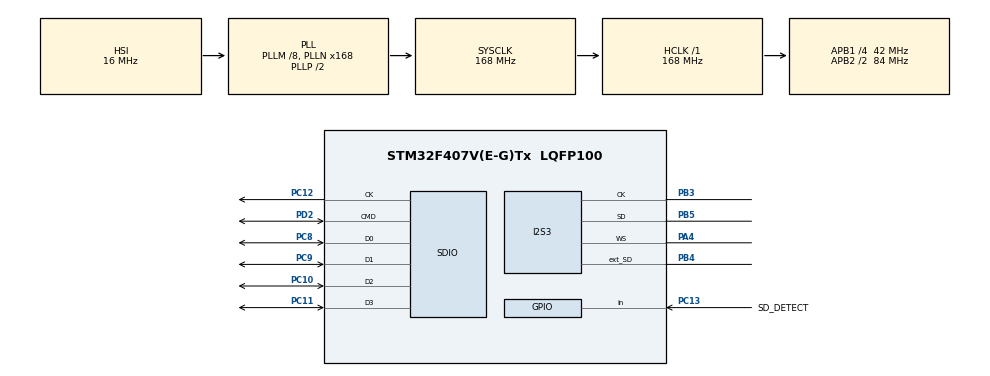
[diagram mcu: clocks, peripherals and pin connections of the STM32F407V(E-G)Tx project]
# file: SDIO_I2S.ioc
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Dma.Request0=SPI3_TX
Dma.SPI3_TX.0.Direction=DMA_MEMORY_TO_PERIPH
Dma.SPI3_TX.0.FIFOMode=DMA_FIFOMODE_ENABLE
Dma.SPI3_TX.0.FIFOThreshold=DMA_FIFO_THRESHOLD_FULL
Dma.SPI3_TX.0.Instance=DMA1_Stream5
Dma.SPI3_TX.0.MemBurst=DMA_MBURST_SINGLE
Dma.SPI3_TX.0.MemDataAlignment=DMA_MDATAALIGN_HALFWORD
Dma.SPI3_TX.0.MemInc=DMA_MINC_ENABLE
Dma.SPI3_TX.0.Mode=DMA_CIRCULAR
Dma.SPI3_TX.0.PeriphBurst=DMA_PBURST_SINGLE
Dma.SPI3_TX.0.PeriphDataAlignment=DMA_PDATAALIGN_HALFWORD
Dma.SPI3_TX.0.PeriphInc=DMA_PINC_DISABLE
Dma.SPI3_TX.0.Priority=DMA_PRIORITY_LOW
FATFS.BSP.number=1
FATFS0.BSP.STBoard=false
FATFS0.BSP.api=Unknown
FATFS0.BSP.instance=PC13-ANTI_TAMP
FATFS0.BSP.ip=GPIO
FATFS0.BSP.mode=Input
FATFS0.BSP.name=Detect_SDIO
FATFS0.BSP.solution=PC13-ANTI_TAMP
I2S3.AudioFreq=I2S_AUDIOFREQ_44K
I2S3.ErrorAudioFreq=-1.35 %
I2S3.FullDuplexMode=I2S_FULLDUPLEXMODE_ENABLE
I2S3.Instance=SPI$Index
I2S3.RealAudioFreq=43.402 KHz
I2S3.VirtualMode=I2S_MODE_MASTER
Mcu.Family=STM32F4
Mcu.Name=STM32F407V(E-G)Tx
Mcu.Package=LQFP100
NVIC.DMA1_Stream5_IRQn=true\:0\:0\:false\:false\:true\:false\:true\:true
NVIC.PriorityGroup=NVIC_PRIORITYGROUP_4
PA13.Mode=Serial_Wire
PA13.Signal=SYS_JTMS-SWDIO
PA14.Mode=Serial_Wire
PA14.Signal=SYS_JTCK-SWCLK
PA4.Mode=Full_Duplex_Master
PA4.Signal=I2S3_WS
PB3.Mode=Full_Duplex_Master
PB3.Signal=I2S3_CK
PB4.Mode=Full_Duplex_Master
PB4.Signal=I2S3_ext_SD
PB5.Mode=Full_Duplex_Master
PB5.Signal=I2S3_SD
PC10.Mode=SD_4_bits_Wide_bus
PC10.Signal=SDIO_D2
PC11.Mode=SD_4_bits_Wide_bus
PC11.Signal=SDIO_D3
PC12.Mode=SD_4_bits_Wide_bus
PC12.Signal=SDIO_CK
PC13-ANTI_TAMP.GPIO_Label=SD_DETECT
PC13-ANTI_TAMP.Signal=GPIO_Input
PC8.Mode=SD_4_bits_Wide_bus
PC8.Signal=SDIO_D0
PC9.Mode=SD_4_bits_Wide_bus
PC9.Signal=SDIO_D1
PD2.Mode=SD_4_bits_Wide_bus
PD2.Signal=SDIO_CMD
PH0-OSC_IN.Mode=HSE-External-Oscillator
PH0-OSC_IN.Signal=RCC_OSC_IN
PH1-OSC_OUT.Mode=HSE-External-Oscillator
PH1-OSC_OUT.Signal=RCC_OSC_OUT
ProjectManager.HeapSize=0x200
ProjectManager.StackSize=0x400
ProjectManager.TargetToolchain=STM32CubeIDE
RCC.48MHZClocksFreq_Value=48000000
RCC.AHBFreq_Value=168000000
RCC.APB1CLKDivider=RCC_HCLK_DIV4
RCC.APB1Freq_Value=42000000
RCC.APB1TimFreq_Value=84000000
RCC.APB2CLKDivider=RCC_HCLK_DIV2
RCC.APB2Freq_Value=84000000
RCC.APB2TimFreq_Value=168000000
RCC.CortexFreq_Value=168000000
RCC.HCLKFreq_Value=168000000
RCC.HSE_VALUE=25000000
RCC.HSI_VALUE=16000000
RCC.LSE_VALUE=32768
RCC.PLLI2SN=50
RCC.PLLM=8
RCC.PLLN=168
RCC.PLLQ=7
RCC.SYSCLKFreq_VALUE=168000000
RCC.SYSCLKSource=RCC_SYSCLKSOURCE_PLLCLK
RCC.VCOOutputFreq_Value=336000000
VP_FATFS_VS_SDIO.Mode=SDIO
board=custom

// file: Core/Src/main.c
/* USER CODE BEGIN Header */
/**
  ******************************************************************************
  * @file           : main.c
  * @brief          : Main program body
  ******************************************************************************
  * @attention
  *
  * Copyright (c) 2025 STMicroelectronics.
  * All rights reserved.
  *
  * This software is licensed under terms that can be found in the LICENSE file
  * in the root directory of this software component.
  * If no LICENSE file comes with this software, it is provided AS-IS.
  *
  ******************************************************************************
  */
/* USER CODE END Header */
#include "main.h"
#include "dma.h"
#include "fatfs.h"
#include "i2s.h"
#include "sdio.h"
#include "gpio.h"

/* USER CODE BEGIN PV */
FATFS fatfs;
FIL myfile;
FRESULT fresult;
UINT bytes_read;
/* USER CODE END PV */

void SystemClock_Config(void);

int main(void)
{

  /* MCU Configuration--------------------------------------------------------*/

  /* Reset of all peripherals, Initializes the Flash interface and the Systick. */
  HAL_Init();

  /* Configure the system clock */
  SystemClock_Config();

  /* Initialize all configured peripherals */
  MX_GPIO_Init();
  MX_DMA_Init();
  MX_I2S3_Init();
  MX_SDIO_SD_Init();
  MX_FATFS_Init();

  /* Infinite loop */
  while (1)
  {

  }
}

void SystemClock_Config(void)
{
  RCC_OscInitTypeDef RCC_OscInitStruct = {0};
  RCC_ClkInitTypeDef RCC_ClkInitStruct = {0};

  /** Configure the main internal regulator output voltage
  */
  __HAL_RCC_PWR_CLK_ENABLE();
  __HAL_PWR_VOLTAGESCALING_CONFIG(PWR_REGULATOR_VOLTAGE_SCALE1);

  /** Initializes the RCC Oscillators according to the specified parameters
  * in the RCC_OscInitTypeDef structure.
  */
  RCC_OscInitStruct.OscillatorType = RCC_OSCILLATORTYPE_HSI;
  RCC_OscInitStruct.HSIState = RCC_HSI_ON;
  RCC_OscInitStruct.HSICalibrationValue = RCC_HSICALIBRATION_DEFAULT;
  RCC_OscInitStruct.PLL.PLLState = RCC_PLL_ON;
  RCC_OscInitStruct.PLL.PLLSource = RCC_PLLSOURCE_HSI;
  RCC_OscInitStruct.PLL.PLLM = 8;
  RCC_OscInitStruct.PLL.PLLN = 168;
  RCC_OscInitStruct.PLL.PLLP = RCC_PLLP_DIV2;
  RCC_OscInitStruct.PLL.PLLQ = 7;
  if (HAL_RCC_OscConfig(&RCC_OscInitStruct) != HAL_OK)
  {
    Error_Handler();
  }

  /** Initializes the CPU, AHB and APB buses clocks
  */
  RCC_ClkInitStruct.ClockType = RCC_CLOCKTYPE_HCLK|RCC_CLOCKTYPE_SYSCLK
                              |RCC_CLOCKTYPE_PCLK1|RCC_CLOCKTYPE_PCLK2;
  RCC_ClkInitStruct.SYSCLKSource = RCC_SYSCLKSOURCE_PLLCLK;
  RCC_ClkInitStruct.AHBCLKDivider = RCC_SYSCLK_DIV1;
  RCC_ClkInitStruct.APB1CLKDivider = RCC_HCLK_DIV4;
  RCC_ClkInitStruct.APB2CLKDivider = RCC_HCLK_DIV2;

  if (HAL_RCC_ClockConfig(&RCC_ClkInitStruct, FLASH_LATENCY_5) != HAL_OK)
  {
    Error_Handler();
  }
}

void Error_Handler(void)
{
  __disable_irq();
  while (1)
  {
  }
}
